# PIC32CX5109BZ31032 device description
Architecture: CORTEX-M4; Family: PIC32CX; Series: PIC32CXBZ31
Registers are 32-bit, read-write, reset 0x0 unless marked. A register's access mark holds for its fields unless they carry their own. Offsets are from the block's base; [hi:lo] are bit positions; {n}, {i} and the like mark numbered series; 'fields as' and 'values as' point back to an identical list; <NAME> marks a mode.

## ITM — Instrumentation Trace Macrocell
Instances: ITM 0xE0000000
{0x0+4i} PORT[{i}] (i=0..31) wo reset not defined — ITM Stimulus Port Registers
  [7:0] PORT <BYTE>, [15:0] PORT <HWORD>, [31:0] PORT <WORD>
0xE00 TER reset not defined — ITM Trace Enable Register
0xE40 TPR reset not defined — ITM Trace Privilege Register
  [3:0] PRIVMASK
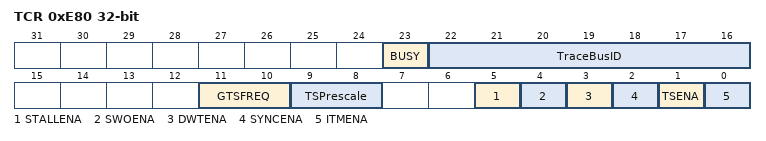
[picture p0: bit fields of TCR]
0xE80 TCR reset not defined — ITM Trace Control Register
  [23] BUSY, [22:16] TraceBusID, [11:10] GTSFREQ, [9:8] TSPrescale, [5] STALLENA, [4] SWOENA, [3] DWTENA, [2] SYNCENA, [1] TSENA, [0] ITMENA
0xEF8 IWR wo reset not defined — ITM Integration Write Register
  [0] ATVALIDM
0xEFC IRR ro reset not defined — ITM Integration Read Register
  [0] ATREADYM
0xFD0 PID4 ro reset 0x4 — ITM Peripheral Identification Register #4
{0xFC0+4i} PID{i} ro (i=5..7) — ITM Peripheral Identification Register #{i}
0xFE0 PID0 ro reset 0x1 — ITM Peripheral Identification Register #0
0xFE4 PID1 ro reset 0xB0 — ITM Peripheral Identification Register #1
0xFE8 PID2 ro reset 0x3B — ITM Peripheral Identification Register #2
0xFEC PID3 ro — ITM Peripheral Identification Register #3
0xFF0 CID0 ro reset 0xD — ITM Component Identification Register #0
0xFF4 CID1 ro reset 0xE0 — ITM Component Identification Register #1
0xFF8 CID2 ro reset 0x5 — ITM Component Identification Register #2
0xFFC CID3 ro reset 0xB1 — ITM Component Identification Register #3

## MPU — Memory Protection Unit
Instances: MPU 0xE000ED90
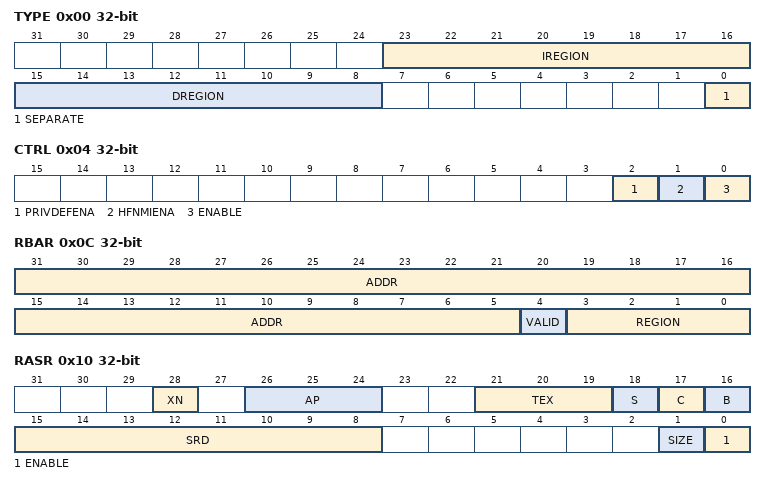
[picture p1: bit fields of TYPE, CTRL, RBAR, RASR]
0x00 TYPE ro reset not defined — MPU Type Register
  [23:16] IREGION — Number of Instruction Regions
  [15:8] DREGION — Number of Data Regions
  [0] SEPARATE — Separate instruction and Data Memory MapsRegions
0x04 CTRL reset not defined — MPU Control Register
  [2] PRIVDEFENA — Enables privileged software access to default memory map
  [1] HFNMIENA — Enable Hard Fault and NMI handlers
  [0] ENABLE — MPU Enable
0x08 RNR reset not defined — MPU Region Number Register
  [7:0] REGION — Region referenced by RBAR and RASR
0x0C RBAR reset not defined — MPU Region Base Address Register
  [31:5] ADDR — Region base address
  [4] VALID — Region number valid
  [3:0] REGION — Region number
0x10 RASR reset not defined — MPU Region Attribute and Size Register
  [28] XN — Execute Never Attribute
  [26:24] AP — Access Permission
  [21:19] TEX — TEX bit
  [18] S — Shareable bit
  [17] C — Cacheable bit
  [16] B — Bufferable bit
  [15:8] SRD — Sub-region disable
  [1] SIZE — Region Size
  [0] ENABLE — Region Enable
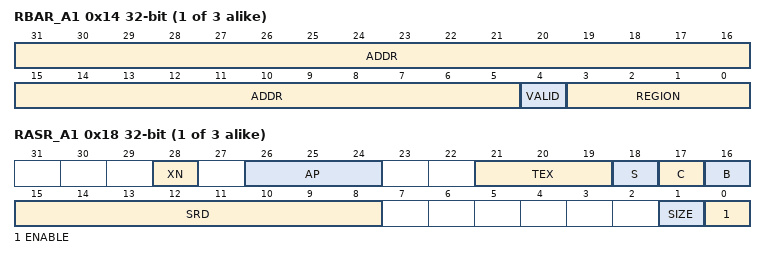
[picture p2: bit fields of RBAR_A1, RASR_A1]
{0xC+8i} RBAR_A{i} reset not defined (i=1..3) — MPU Alias {i} Region Base Address Register
  fields as RBAR
{0x10+8i} RASR_A{i} reset not defined (i=1..3) — MPU Alias {i} Region Attribute and Size Register
  fields as RASR

## NVIC — Nested Vectored Interrupt Controller
Instances: NVIC 0xE000E100
{0x0+4i} ISER[{i}] (i=0..1) — Interrupt Set Enable Register
  [31:0] SETENA — Interrupt set enable bits
{0x80+4i} ICER[{i}] (i=0..1) — Interrupt Clear Enable Register
  [31:0] CLRENA — Interrupt clear-enable bits
{0x100+4i} ISPR[{i}] (i=0..1) — Interrupt Set Pending Register
  [31:0] SETPEND — Interrupt set-pending bits
{0x180+4i} ICPR[{i}] (i=0..1) — Interrupt Clear Pending Register
  [31:0] CLRPEND — Interrupt clear-pending bits
{0x200+4i} IABR[{i}] (i=0..1) — Interrupt Active Bit Register
  [31:0] ACTIVE — Interrupt active bits
{0x300+i} IP[{i}] (i=0..42) 8-bit — Interrupt Priority Register n
  [2:0] PRI0 — Priority of interrupt n
0xE00 STIR wo reset not defined — Software Trigger Interrupt Register
  [8:0] INTID — Interrupt ID to trigger

## ROT — Secure Root of Trust Macro
Instances: ROT 0x44002C00
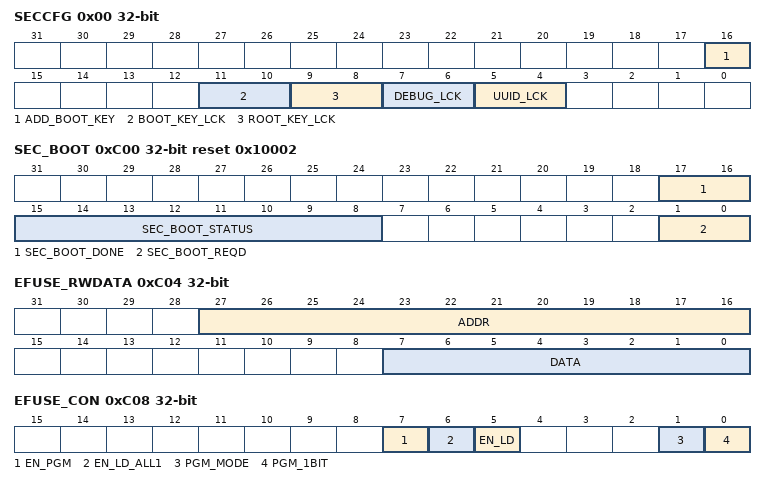
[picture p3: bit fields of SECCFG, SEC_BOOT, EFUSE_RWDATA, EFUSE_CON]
0x00 SECCFG — Secure Configuration HOLDING REGISTER1,2
  [16] ADD_BOOT_KEY — Additional boot Key bit
  [11:10] BOOT_KEY_LCK — Lock bits for Secure Boot/OTA Key
    0=Secure boot key is not locked; 1=Secure boot key is locked and cannot be programmed; 2=Secure boot key is locked and cannot be programmed; 3=Secure boot key is locked and cannot be programmed
  [9:8] ROOT_KEY_LCK — Lock bits for storage root Key
    0=Storage root key is not locked; 1=Storage root key is locked and cannot be programmed; 2=Storage root key is locked and cannot be programmed; 3=Storage root key is locked and cannot be programmed
  [7:6] DEBUG_LCK — Lock bits for debug/programming
    0=Debug is not locked; 1=Debug is locked; 2=Debug is locked; 3=Debug is locked
  [5:4] UUID_LCK — Programming lock bits for Unique ID fuses
    0=Unique ID is not locked; 1=Unique ID is locked and cannot be programmed; 2=Unique ID is locked and cannot be programmed; 3=Unique ID is locked and cannot be programmed
0xC00 SEC_BOOT reset 0x10002 — Secure Boot Register
  [17:16] SEC_BOOT_DONE — Bits to indicate that secure boot is done
    0=S ecure boot is done; 1=S ecure boot is not done; 2=S ecure boot is not done; 3=S ecure boot is done
  [15:8] SEC_BOOT_STATUS — Bits to indicate that secure boot status
  [1:0] SEC_BOOT_REQD — Bits to indicate that secure boot is required on the next device reset.
    0=S ecure boot code authentication is required; 1=S ecure boot code authentication is NOT required; 2=S ecure boot code authentication is NOT required; 3=S ecure boot code authentication is required
0xC04 EFUSE_RWDATA
  [27:16] ADDR — eFuse Program/Read Address
  [7:0] DATA — eFuse Program (Write) Data
0xC08 EFUSE_CON — Efuse Configuration Register2
  [7] EN_PGM — eFuse Programming Start bit
    0=EFuse Programming operation has completed; 1=Start eFuse Programming operation
  [6] EN_LD_ALL1 — eFuse Panel Read Start bit for loading into the holding registers
    0=EFuse Read operation has completed; 1=Start eFuse Read operation for entire eFuse panel
  [5] EN_LD — eFuse Word Read Start bit for loading the fuse byte pointed by ADDR field into the holding register
    0=EFuse Read operation has completed; 1=Start eFuse Read operation for specified eFuse word as addressed in EFUSE_RWDATA register
  [1] PGM_MODE — eFuse Programming Mode Enable bit
    0=EFuse Programming disabled; 1=EFuse Programming enabled
  [0] PGM_1BIT — eFuse CTRL to program 1 bit at a time. Valid only when EN_PGM is set
    0=EFuse controller will program EFUSE_RWDATA.DATA[15:0] to the address in EFUSE_RWDATA.ADDR[11:3]; 1=EFuse controller will program EFUSE_RWDATA.DATA[0] to the address in EFUSE_RWDATA.ADDR[11:0]
